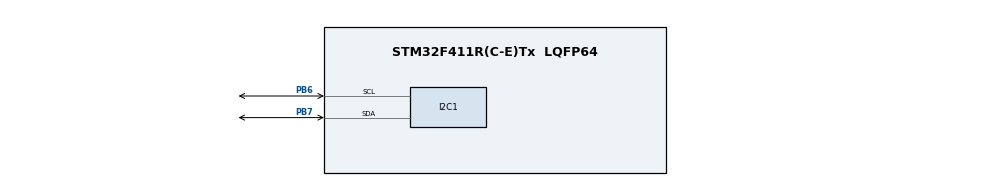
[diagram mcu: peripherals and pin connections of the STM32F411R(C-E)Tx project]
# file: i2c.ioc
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Mcu.Family=STM32F4
Mcu.Name=STM32F411R(C-E)Tx
Mcu.Package=LQFP64
NVIC.PriorityGroup=NVIC_PRIORITYGROUP_4
PB6.Mode=I2C
PB6.Signal=I2C1_SCL
PB7.Mode=I2C
PB7.Signal=I2C1_SDA
ProjectManager.TargetToolchain=EWARM
RCC.AHBFreq_Value=16000000
RCC.APB1Freq_Value=16000000
RCC.APB2Freq_Value=16000000
RCC.CortexFreq_Value=16000000
RCC.HSE_VALUE=25000000
RCC.HSI_VALUE=16000000
RCC.LSE_VALUE=32768
RCC.SYSCLKFreq_VALUE=16000000
RCC.VCOOutputFreq_Value=192000000
board=i2c

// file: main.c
#include "stm32f4xx_hal.h"
#include "stm32f4xx_hal_conf.h"
 #include "stm32f4xx_hal_i2c.h"

I2C_HandleTypeDef hi2c1;

/* USER CODE BEGIN PV */
/* Private variables ---------------------------------------------------------*/

/* USER CODE END PV */

void SystemClock_Config(void);
static void MX_GPIO_Init(void);
static void MX_I2C1_Init(void);

/* USER CODE BEGIN PFP */
/* Private function prototypes -----------------------------------------------*/

/* USER CODE END PFP */

/* USER CODE BEGIN 0 */

#define SIZE 5
uint8_t MasterTX[SIZE] = {1, 2, 3, 4, 5};
uint8_t slave[SIZE];
void HAL_I2C_SlaveRxCpltCallback(I2C_HandleTypeDef *hi2c);

/* USER CODE END 0 */

int main(void)
{

  /* MCU Configuration----------------------------------------------------------*/

  /* Reset of all peripherals, Initializes the Flash interface and the Systick. */
  HAL_Init();

  /* Configure the system clock */
  SystemClock_Config();

  /* Initialize all configured peripherals */
	HAL_MspInit();
	MX_GPIO_Init();

	HAL_I2C_MspInit(hi2c1);
	MX_I2C1_Init();

  /* USER CODE BEGIN 2 */

	//HAL_I2C_Slave_Receive_IT(hi2c1, (uint8_t *)slave, SIZE)

/* USER CODE END 2 */

  /* Infinite loop */
  /* USER CODE BEGIN WHILE */
  while (1)
  {
	HAL_I2C_Master_Transmit(&hi2c1, (0X76 << 1), (uint8_t *)MasterTX, SIZE, 0xFFFFFF);

	  /* Insert a 500ms delay */
		HAL_Delay(500);

  }
  /* USER CODE END 3 */

}

/** System Clock Configuration
*/
void SystemClock_Config(void)
{

  RCC_OscInitTypeDef RCC_OscInitStruct;

  __PWR_CLK_ENABLE();

  __HAL_PWR_VOLTAGESCALING_CONFIG(PWR_REGULATOR_VOLTAGE_SCALE1);

  RCC_OscInitStruct.OscillatorType = RCC_OSCILLATORTYPE_HSI;
  RCC_OscInitStruct.HSIState = RCC_HSI_ON;
  RCC_OscInitStruct.HSICalibrationValue = 16;
  RCC_OscInitStruct.PLL.PLLState = RCC_PLL_NONE;
  HAL_RCC_OscConfig(&RCC_OscInitStruct);

  HAL_SYSTICK_Config(HAL_RCC_GetHCLKFreq()/1000);

  HAL_SYSTICK_CLKSourceConfig(SYSTICK_CLKSOURCE_HCLK);

  /* SysTick_IRQn interrupt configuration */
  HAL_NVIC_SetPriority(SysTick_IRQn, 0, 0);
}

/* I2C1 init function */
void MX_I2C1_Init(void)
{

  hi2c1.Instance = I2C1;
  hi2c1.Init.ClockSpeed = 100000;
  hi2c1.Init.DutyCycle = I2C_DUTYCYCLE_2;
  hi2c1.Init.OwnAddress1 = 0;
  hi2c1.Init.AddressingMode = I2C_ADDRESSINGMODE_7BIT;
  hi2c1.Init.DualAddressMode = I2C_DUALADDRESS_DISABLED;
  hi2c1.Init.OwnAddress2 = 0;
  hi2c1.Init.GeneralCallMode = I2C_GENERALCALL_DISABLED;
  hi2c1.Init.NoStretchMode = I2C_NOSTRETCH_DISABLED;
  HAL_I2C_Init(&hi2c1);

}

/** Pinout Configuration
*/
void MX_GPIO_Init(void)
{

  /* GPIO Ports Clock Enable */
  __GPIOB_CLK_ENABLE();

}

/* USER CODE BEGIN 4 */
void HAL_I2C_SlaveRxCpltCallback(I2C_HandleTypeDef *hi2c)
{
	if(hi2c->Instance == hi2c1.Instance)
	{

	}
}
/* USER CODE END 4 */

/************************ (C) COPYRIGHT STMicroelectronics *****END OF FILE****/
